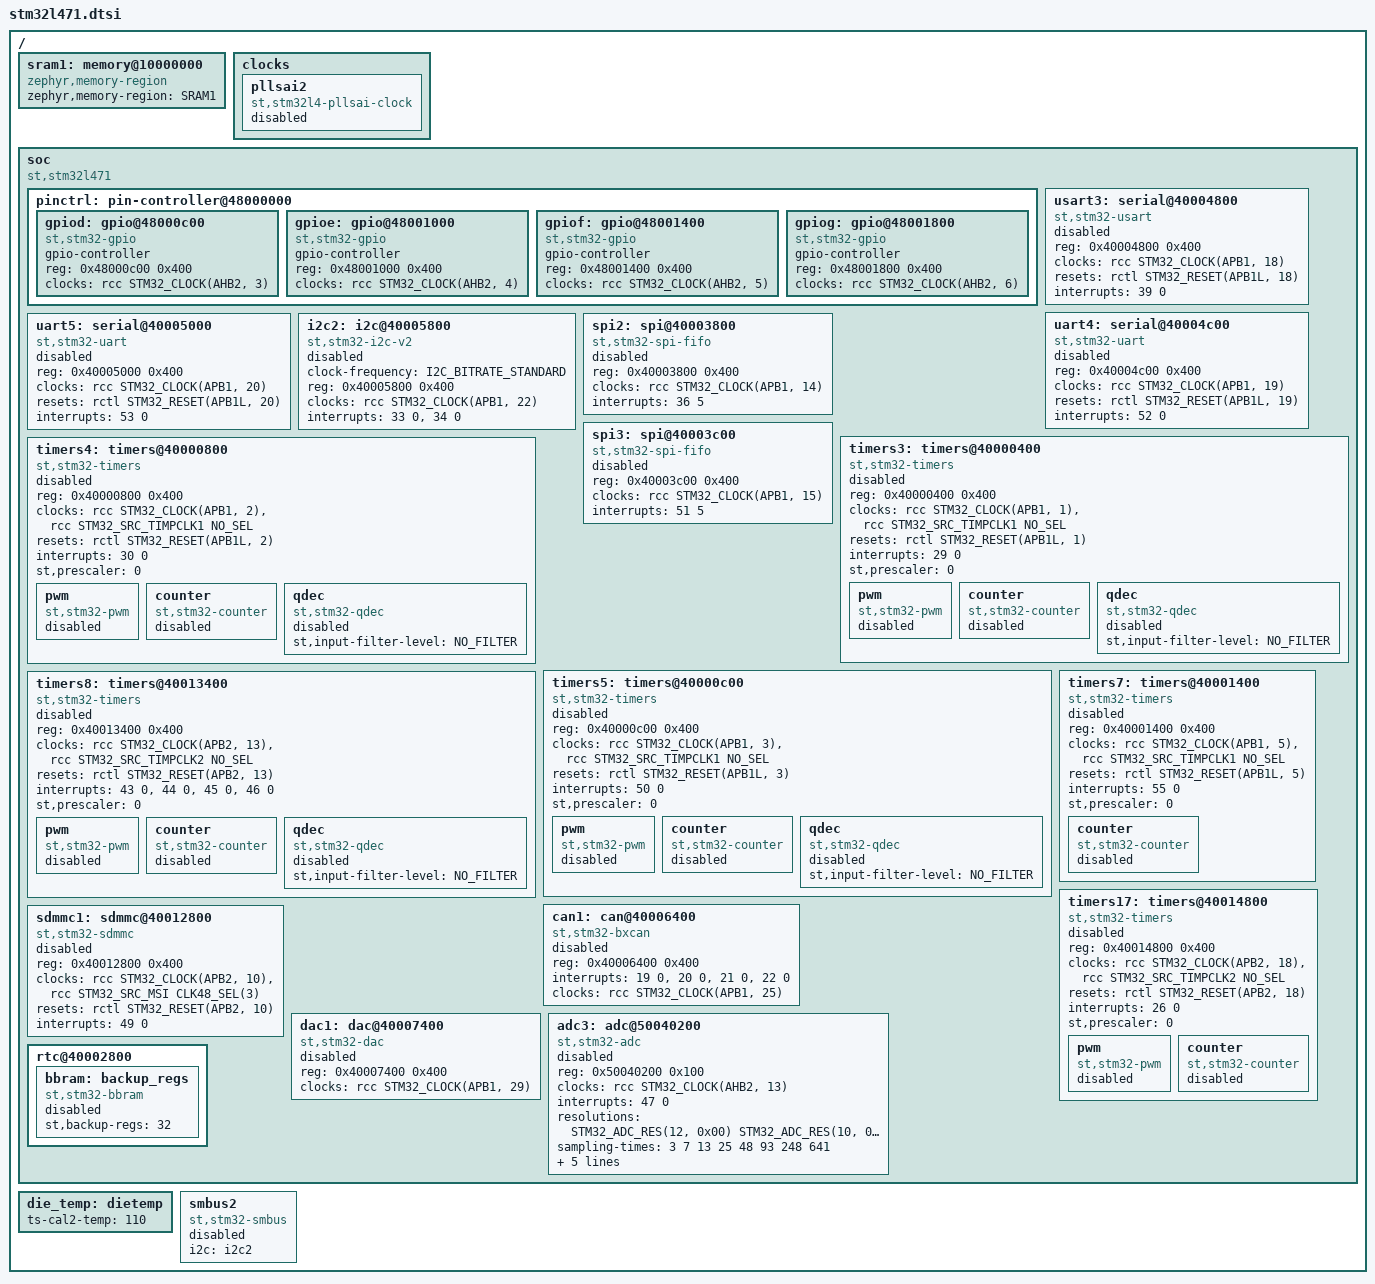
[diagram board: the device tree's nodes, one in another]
/*
 * Copyright (c) 2017 Linaro Limited
 *
 * SPDX-License-Identifier: Apache-2.0
 */

#include <st/l4/stm32l4.dtsi>
#include <st/l4/stm32l4_sai.dtsi>
#include <zephyr/dt-bindings/sensor/qdec_stm32.h>

/ {
	sram1: memory@10000000 {
		compatible = "zephyr,memory-region", "mmio-sram";
		zephyr,memory-region = "SRAM1";
	};

	clocks {
		pllsai2: pllsai2 {
			#clock-cells = <0>;
			compatible = "st,stm32l4-pllsai-clock";
			status = "disabled";
		};
	};

	soc {
		compatible = "st,stm32l471", "st,stm32l4", "simple-bus";

		pinctrl: pin-controller@48000000 {
			gpiod: gpio@48000c00 {
				compatible = "st,stm32-gpio";
				gpio-controller;
				#gpio-cells = <2>;
				reg = <0x48000c00 0x400>;
				clocks = <&rcc STM32_CLOCK(AHB2, 3)>;
			};

			gpioe: gpio@48001000 {
				compatible = "st,stm32-gpio";
				gpio-controller;
				#gpio-cells = <2>;
				reg = <0x48001000 0x400>;
				clocks = <&rcc STM32_CLOCK(AHB2, 4)>;
			};

			gpiof: gpio@48001400 {
				compatible = "st,stm32-gpio";
				gpio-controller;
				#gpio-cells = <2>;
				reg = <0x48001400 0x400>;
				clocks = <&rcc STM32_CLOCK(AHB2, 5)>;
			};

			gpiog: gpio@48001800 {
				compatible = "st,stm32-gpio";
				gpio-controller;
				#gpio-cells = <2>;
				reg = <0x48001800 0x400>;
				clocks = <&rcc STM32_CLOCK(AHB2, 6)>;
			};
		};

		usart3: serial@40004800 {
			compatible = "st,stm32-usart", "st,stm32-uart";
			reg = <0x40004800 0x400>;
			clocks = <&rcc STM32_CLOCK(APB1, 18)>;
			resets = <&rctl STM32_RESET(APB1L, 18)>;
			interrupts = <39 0>;
			status = "disabled";
		};

		uart4: serial@40004c00 {
			compatible = "st,stm32-uart";
			reg = <0x40004c00 0x400>;
			clocks = <&rcc STM32_CLOCK(APB1, 19)>;
			resets = <&rctl STM32_RESET(APB1L, 19)>;
			interrupts = <52 0>;
			status = "disabled";
		};

		uart5: serial@40005000 {
			compatible = "st,stm32-uart";
			reg = <0x40005000 0x400>;
			clocks = <&rcc STM32_CLOCK(APB1, 20)>;
			resets = <&rctl STM32_RESET(APB1L, 20)>;
			interrupts = <53 0>;
			status = "disabled";
		};

		i2c2: i2c@40005800 {
			compatible = "st,stm32-i2c-v2";
			clock-frequency = <I2C_BITRATE_STANDARD>;
			#address-cells = <1>;
			#size-cells = <0>;
			reg = <0x40005800 0x400>;
			clocks = <&rcc STM32_CLOCK(APB1, 22)>;
			interrupts = <33 0>, <34 0>;
			interrupt-names = "event", "error";
			status = "disabled";
		};

		spi2: spi@40003800 {
			compatible = "st,stm32-spi-fifo", "st,stm32-spi";
			#address-cells = <1>;
			#size-cells = <0>;
			reg = <0x40003800 0x400>;
			clocks = <&rcc STM32_CLOCK(APB1, 14)>;
			interrupts = <36 5>;
			status = "disabled";
		};

		spi3: spi@40003c00 {
			compatible = "st,stm32-spi-fifo", "st,stm32-spi";
			#address-cells = <1>;
			#size-cells = <0>;
			reg = <0x40003c00 0x400>;
			clocks = <&rcc STM32_CLOCK(APB1, 15)>;
			interrupts = <51 5>;
			status = "disabled";
		};

		timers3: timers@40000400 {
			compatible = "st,stm32-timers";
			reg = <0x40000400 0x400>;
			clocks = <&rcc STM32_CLOCK(APB1, 1)>,
				 <&rcc STM32_SRC_TIMPCLK1 NO_SEL>;
			resets = <&rctl STM32_RESET(APB1L, 1)>;
			interrupts = <29 0>;
			interrupt-names = "global";
			st,prescaler = <0>;
			status = "disabled";

			pwm {
				compatible = "st,stm32-pwm";
				status = "disabled";
				#pwm-cells = <3>;
			};

			counter {
				compatible = "st,stm32-counter";
				status = "disabled";
			};

			qdec {
				compatible = "st,stm32-qdec";
				st,input-filter-level = <NO_FILTER>;
				status = "disabled";
			};
		};

		timers4: timers@40000800 {
			compatible = "st,stm32-timers";
			reg = <0x40000800 0x400>;
			clocks = <&rcc STM32_CLOCK(APB1, 2)>,
				 <&rcc STM32_SRC_TIMPCLK1 NO_SEL>;
			resets = <&rctl STM32_RESET(APB1L, 2)>;
			interrupts = <30 0>;
			interrupt-names = "global";
			st,prescaler = <0>;
			status = "disabled";

			pwm {
				compatible = "st,stm32-pwm";
				status = "disabled";
				#pwm-cells = <3>;
			};

			counter {
				compatible = "st,stm32-counter";
				status = "disabled";
			};

			qdec {
				compatible = "st,stm32-qdec";
				st,input-filter-level = <NO_FILTER>;
				status = "disabled";
			};
		};

		timers5: timers@40000c00 {
			compatible = "st,stm32-timers";
			reg = <0x40000c00 0x400>;
			clocks = <&rcc STM32_CLOCK(APB1, 3)>,
				 <&rcc STM32_SRC_TIMPCLK1 NO_SEL>;
			resets = <&rctl STM32_RESET(APB1L, 3)>;
			interrupts = <50 0>;
			interrupt-names = "global";
			st,prescaler = <0>;
			status = "disabled";

			pwm {
				compatible = "st,stm32-pwm";
				status = "disabled";
				#pwm-cells = <3>;
			};

			counter {
				compatible = "st,stm32-counter";
				status = "disabled";
			};

			qdec {
				compatible = "st,stm32-qdec";
				st,input-filter-level = <NO_FILTER>;
				status = "disabled";
			};
		};

		timers7: timers@40001400 {
			compatible = "st,stm32-timers";
			reg = <0x40001400 0x400>;
			clocks = <&rcc STM32_CLOCK(APB1, 5)>,
				 <&rcc STM32_SRC_TIMPCLK1 NO_SEL>;
			resets = <&rctl STM32_RESET(APB1L, 5)>;
			interrupts = <55 0>;
			interrupt-names = "global";
			st,prescaler = <0>;
			status = "disabled";

			counter {
				compatible = "st,stm32-counter";
				status = "disabled";
			};
		};

		timers8: timers@40013400 {
			compatible = "st,stm32-timers";
			reg = <0x40013400 0x400>;
			clocks = <&rcc STM32_CLOCK(APB2, 13)>,
				 <&rcc STM32_SRC_TIMPCLK2 NO_SEL>;
			resets = <&rctl STM32_RESET(APB2, 13)>;
			interrupts = <43 0>, <44 0>, <45 0>, <46 0>;
			interrupt-names = "brk", "up", "trgcom", "cc";
			st,prescaler = <0>;
			status = "disabled";

			pwm {
				compatible = "st,stm32-pwm";
				status = "disabled";
				#pwm-cells = <3>;
			};

			counter {
				compatible = "st,stm32-counter";
				status = "disabled";
			};

			qdec {
				compatible = "st,stm32-qdec";
				st,input-filter-level = <NO_FILTER>;
				status = "disabled";
			};
		};

		timers17: timers@40014800 {
			compatible = "st,stm32-timers";
			reg = <0x40014800 0x400>;
			clocks = <&rcc STM32_CLOCK(APB2, 18)>,
				 <&rcc STM32_SRC_TIMPCLK2 NO_SEL>;
			resets = <&rctl STM32_RESET(APB2, 18)>;
			interrupts = <26 0>;
			interrupt-names = "global";
			st,prescaler = <0>;
			status = "disabled";

			pwm {
				compatible = "st,stm32-pwm";
				status = "disabled";
				#pwm-cells = <3>;
			};

			counter {
				compatible = "st,stm32-counter";
				status = "disabled";
			};
		};

		can1: can@40006400 {
			compatible = "st,stm32-bxcan";
			reg = <0x40006400 0x400>;
			interrupts = <19 0>, <20 0>, <21 0>, <22 0>;
			interrupt-names = "TX", "RX0", "RX1", "SCE";
			clocks = <&rcc STM32_CLOCK(APB1, 25)>;
			status = "disabled";
		};

		sdmmc1: sdmmc@40012800 {
			compatible = "st,stm32-sdmmc";
			reg = <0x40012800 0x400>;
			clocks = <&rcc STM32_CLOCK(APB2, 10)>,
				 <&rcc STM32_SRC_MSI CLK48_SEL(3)>;
			resets = <&rctl STM32_RESET(APB2, 10)>;
			interrupts = <49 0>;
			status = "disabled";
		};

		dac1: dac@40007400 {
			compatible = "st,stm32-dac";
			reg = <0x40007400 0x400>;
			clocks = <&rcc STM32_CLOCK(APB1, 29)>;
			status = "disabled";
			#io-channel-cells = <1>;
		};

		adc3: adc@50040200 {
			compatible = "st,stm32-adc";
			reg = <0x50040200 0x100>;
			clocks = <&rcc STM32_CLOCK(AHB2, 13)>;
			clock-names = "adcx";
			interrupts = <47 0>;
			#io-channel-cells = <1>;
			resolutions = <STM32_ADC_RES(12, 0x00)
				       STM32_ADC_RES(10, 0x01)
				       STM32_ADC_RES(8, 0x02)
				       STM32_ADC_RES(6, 0x03)>;
			sampling-times = <3 7 13 25 48 93 248 641>;
			st,adc-sequencer = "programmable";
			st,adc-oversampler = "minimal";
			st,adc-internal-regulator = "startup-sw-delay";
			st,adc-has-deep-powerdown;
			st,adc-has-differential-support;
			status = "disabled";
		};

		rtc@40002800 {
			bbram: backup_regs {
				compatible = "st,stm32-bbram";
				st,backup-regs = <32>;
				status = "disabled";
			};
		};
	};

	die_temp: dietemp {
		ts-cal2-temp = <110>;
	};

	smbus2: smbus2 {
		compatible = "st,stm32-smbus";
		#address-cells = <1>;
		#size-cells = <0>;
		i2c = <&i2c2>;
		status = "disabled";
	};
};
